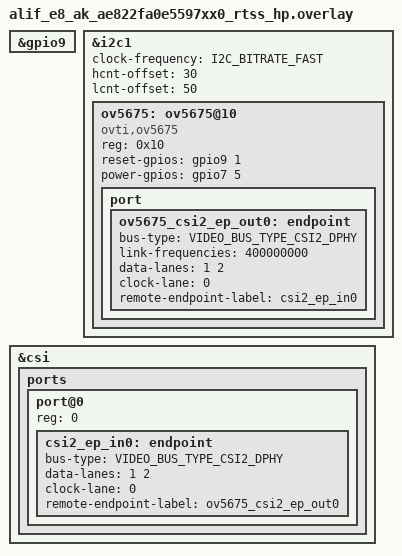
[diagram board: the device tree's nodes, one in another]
/* Copyright (C) 2026 Alif Semiconductor - All Rights Reserved.
 * Use, distribution and modification of this code are permitted under the
 * terms stated in the Alif Semiconductor Software License Agreement.
 *
 * You should have received a copy of the Alif Semiconductor Software
 * License Agreement with this file. If not, please write to:
 * contact@alifsemi.com, or visit: https://alifsemi.com/license
 *
 * E8 AppKit (RTSS-HP) UVC pipeline:
 *   OV5675 (MIPI CSI-2, RAW10) -> ISP (NV12 1024x768) -> Hantro JPEG -> UVC.
 *
 * This overlay is applied automatically for every E8 AppKit build (by board
 * name). The AppKit supports only the OV5675, so unlike the DK there is no
 * separate sensor overlay: the E8 pipeline is shared with the DK in
 * e8_isp_jpeg_uvc.dtsi, and this file adds the sensor. On the AppKit the camera
 * connector sits directly on i2c1 (there is no i2c-mux), with the sensor reset
 * on gpio9.1 (CAMERA_RESET) and its power on gpio7.5 (CAMERA_POWER).
 *
 * Resolution is the same as on the DK: the OV5675 streams its full-FOV
 * 1296x972 RAW10 mode and the ISP downscales it to 1024x768 NV12 (see the DK
 * OV5675 overlay for the rationale).
 */

#include <dt-bindings/i2c/i2c.h>
#include <dt-bindings/gpio/gpio.h>
#include <dt-bindings/video/video-interfaces.h>

#include "e8_isp_jpeg_uvc.dtsi"

/* Camera reset (CAMERA_RESET, gpio9.1). */
&gpio9 {
	status = "okay";
};

/*
 * The OV5675 needs Fast-mode I2C. i2c1 is shared with the display's GT911
 * touch controller (0x5D), which does not collide with the OV5675 (0x10).
 */
&i2c1 {
	clock-frequency = <I2C_BITRATE_FAST>;

	/*
	 * For Standard  speed LCNT=0  and HCNT=0
	 * For Fast      speed LCNT=50 and HCNT=30
	 * For Fast Plus speed LCNT=35 and HCNT=5
	 */
	hcnt-offset = <30>;
	lcnt-offset = <50>;

	/* 0x10 for the compact module, 0x36 for the legacy one. */
	ov5675: ov5675@10 {
		compatible = "ovti,ov5675";
		reg = <0x10>;

		reset-gpios = <&gpio9 1 GPIO_ACTIVE_HIGH>;
		power-gpios = <&gpio7 5 GPIO_ACTIVE_HIGH>;

		status = "okay";

		port {
			ov5675_csi2_ep_out0: endpoint {
				bus-type = <VIDEO_BUS_TYPE_CSI2_DPHY>;
				link-frequencies = < 400000000 >;
				data-lanes = <1 2>;
				clock-lane = <0>;

				remote-endpoint-label = "csi2_ep_in0";
			};
		};
	};
};

/* CSI input endpoint: the OV5675 uses two data lanes. */
&csi {
	ports {
		port@0 {
			reg = <0>;
			csi2_ep_in0: endpoint {
				bus-type = <VIDEO_BUS_TYPE_CSI2_DPHY>;
				data-lanes = <1 2>;
				clock-lane = <0>;

				remote-endpoint-label = "ov5675_csi2_ep_out0";
			};
		};
	};
};
